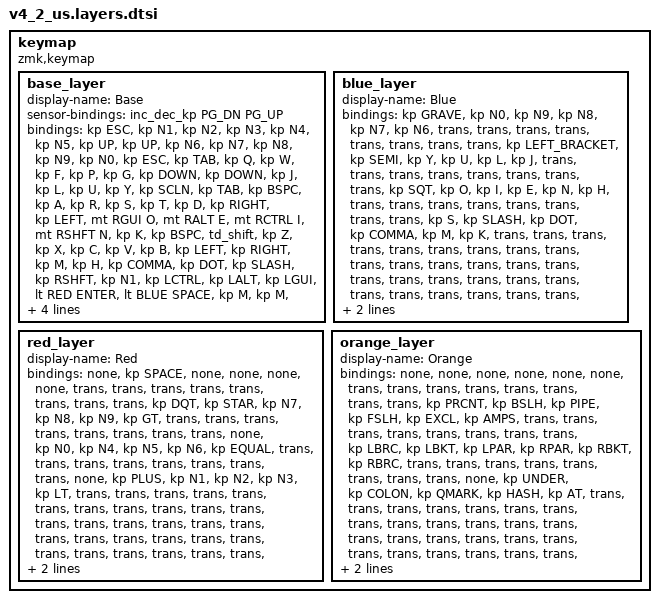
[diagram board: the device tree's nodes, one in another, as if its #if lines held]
/*
 * The layer tables of the US MonoTypist, generated by tools/gen-keymap.mjs from layout/us.json.
 * Do not edit this file: change layout/us.json and run "node tools/gen-keymap.mjs".
 */

keymap {
    compatible = "zmk,keymap";

    base_layer {
        display-name = "Base";
        sensor-bindings = <&inc_dec_kp PG_DN PG_UP>;
        bindings = <
#if SIMPLE_MODE == 1
            &kp ESC        &kp N1         &kp N2         &kp N3         &kp N4         &kp N5         &kp UP         &kp UP         &kp N6         &kp N7         &kp N8         &kp N9         &kp N0         &kp ESC
#else
            &kp ESC        &kp C_AL_CALC  &kp LG(DOT)    &kp LS(LG(S))  &mac_git       &kp LG(V)      &kp UP         &kp UP         &kp N6         &kp N7         &kp N8         &kp N9         &kp N0         &kp ESC
#endif
            &kp TAB        &kp Q          &kp W          &kp F          &kp P          &kp G          &kp DOWN       &kp DOWN       &kp J          &kp L          &kp U          &kp Y          &kp SCLN       &kp TAB
            &kp BSPC       &kp A          &kp R          &kp S          &kp T          &kp D          &kp RIGHT      &kp LEFT       &mt RGUI O     &mt RALT E     &mt RCTRL I    &mt RSHFT N    &kp K          &kp BSPC
            &td_shift      &kp Z          &kp X          &kp C          &kp V          &kp B          &kp LEFT       &kp RIGHT      &kp M          &kp H          &kp COMMA      &kp DOT        &kp SLASH      &kp RSHFT
            &kp N1         &kp LCTRL      &kp LALT       &kp LGUI       &lt RED ENTER  &lt BLUE SPACE &kp M          &kp M          &kp N9         &kp N8         &kp RGUI       &kp BSPC       &lt NAV SPACE  &kp N0
            &kp N4         &kp N5         &kp N6         &kp N7         &kp N8         &lt ORANGE DEL &kp N9         &kp N1         &kp N5         &kp N4         &kp N3         &kp N2         &kp LSHFT      &kp N6
        >;
    };

    blue_layer {
        display-name = "Blue";
        bindings = <
            &kp GRAVE        &kp N0           &kp N9           &kp N8           &kp N7           &kp N6           &trans           &trans           &trans           &trans           &trans           &trans           &trans           &trans
            &kp LEFT_BRACKET &kp SEMI         &kp Y            &kp U            &kp L            &kp J            &trans           &trans           &trans           &trans           &trans           &trans           &trans           &trans
            &kp SQT          &kp O            &kp I            &kp E            &kp N            &kp H            &trans           &trans           &trans           &trans           &trans           &trans           &trans           &trans
            &kp S            &kp SLASH        &kp DOT          &kp COMMA        &kp M            &kp K            &trans           &trans           &trans           &trans           &trans           &trans           &trans           &trans
            &trans           &trans           &trans           &trans           &trans           &trans           &trans           &trans           &trans           &trans           &trans           &trans           &trans           &trans
            &trans           &trans           &trans           &trans           &trans           &trans           &trans           &trans           &trans           &trans           &trans           &trans           &trans           &trans
        >;
    };

    red_layer {
        display-name = "Red";
        bindings = <
            &none     &kp SPACE &none     &none     &none     &none     &trans    &trans    &trans    &trans    &trans    &trans    &trans    &trans
            &kp DQT   &kp STAR  &kp N7    &kp N8    &kp N9    &kp GT    &trans    &trans    &trans    &trans    &trans    &trans    &trans    &trans
            &none     &kp N0    &kp N4    &kp N5    &kp N6    &kp EQUAL &trans    &trans    &trans    &trans    &trans    &trans    &trans    &trans
            &none     &kp PLUS  &kp N1    &kp N2    &kp N3    &kp LT    &trans    &trans    &trans    &trans    &trans    &trans    &trans    &trans
            &trans    &trans    &trans    &trans    &trans    &trans    &trans    &trans    &trans    &trans    &trans    &trans    &trans    &trans
            &trans    &trans    &trans    &trans    &trans    &trans    &trans    &trans    &trans    &trans    &trans    &trans    &trans    &trans
        >;
    };

    orange_layer {
        display-name = "Orange";
        bindings = <
            &none     &none     &none     &none     &none     &none     &trans    &trans    &trans    &trans    &trans    &trans    &trans    &trans
            &kp PRCNT &kp BSLH  &kp PIPE  &kp FSLH  &kp EXCL  &kp AMPS  &trans    &trans    &trans    &trans    &trans    &trans    &trans    &trans
            &kp LBRC  &kp LBKT  &kp LPAR  &kp RPAR  &kp RBKT  &kp RBRC  &trans    &trans    &trans    &trans    &trans    &trans    &trans    &trans
            &none     &kp UNDER &kp COLON &kp QMARK &kp HASH  &kp AT    &trans    &trans    &trans    &trans    &trans    &trans    &trans    &trans
            &trans    &trans    &trans    &trans    &trans    &trans    &trans    &trans    &trans    &trans    &trans    &trans    &trans    &trans
            &trans    &trans    &trans    &trans    &trans    &trans    &trans    &trans    &trans    &trans    &trans    &trans    &trans    &trans
        >;
    };
};
